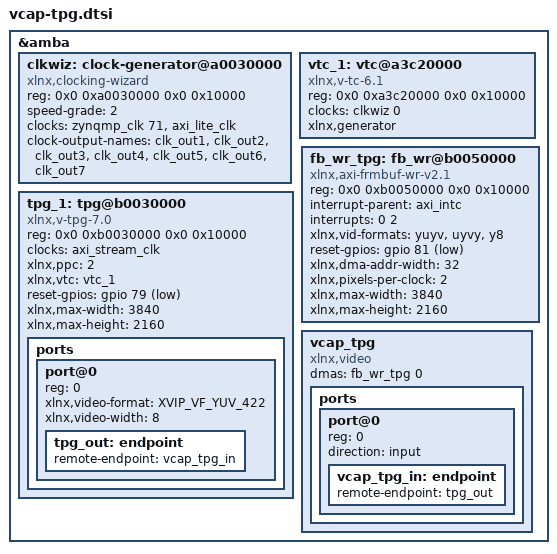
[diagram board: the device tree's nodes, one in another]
#include <dt-bindings/media/xilinx-vip.h>

&amba {

	clkwiz: clock-generator@a0030000 {
		reg = <0x0 0xa0030000 0x0 0x10000>;
		compatible = "xlnx,clocking-wizard";
		#clock-cells = <1>;
		speed-grade = <2>;
		clock-names = "clk_in1", "s_axi_aclk";
		clocks = <&zynqmp_clk 71>, <&axi_lite_clk>;
		clock-output-names = "clk_out1", "clk_out2", "clk_out3",
				     "clk_out4", "clk_out5", "clk_out6",
				     "clk_out7";
	};

	vtc_1: vtc@a3c20000 {
		compatible = "xlnx,v-tc-6.1";
		reg = <0x0 0xa3c20000 0x0 0x10000>;
		clocks = <&clkwiz 0>;
		xlnx,generator;
	};

	tpg_1: tpg@b0030000 {
		compatible = "xlnx,v-tpg-7.0";
		reg = <0x0 0xb0030000 0x0 0x10000>;
		clocks = <&axi_stream_clk>;
		xlnx,ppc = <2>;
		xlnx,vtc = <&vtc_1>;
		reset-gpios = <&gpio 79 1>;
		xlnx,max-width = <3840>;
		xlnx,max-height = <2160>;

		ports {
			#address-cells = <1>;
			#size-cells = <0>;

			port@0 {
				reg = <0>;
				xlnx,video-format = <XVIP_VF_YUV_422>;
				xlnx,video-width = <8>;

				tpg_out: endpoint {
					remote-endpoint = <&vcap_tpg_in>;
				};
			};
		};
	};

	fb_wr_tpg: fb_wr@b0050000 {
		compatible = "xlnx,axi-frmbuf-wr-v2.1";
		reg = <0x0 0xb0050000 0x0 0x10000>;
		#dma-cells = <1>;
		interrupt-parent = <&axi_intc>;
		interrupts = <0 2>;
		xlnx,vid-formats = "yuyv", "uyvy", "y8";
		reset-gpios = <&gpio 81 1>;
		xlnx,dma-addr-width = <32>;
		xlnx,pixels-per-clock = <2>;
		xlnx,max-width = <3840>;
		xlnx,max-height = <2160>;
        };

	vcap_tpg {
		compatible = "xlnx,video";
		dmas = <&fb_wr_tpg 0>;
		dma-names = "port0";

		ports {
			#address-cells = <1>;
			#size-cells = <0>;

			port@0 {
				reg = <0>;
				direction = "input";
				vcap_tpg_in: endpoint {
					remote-endpoint = <&tpg_out>;
				};
			};
		};
	};
};
